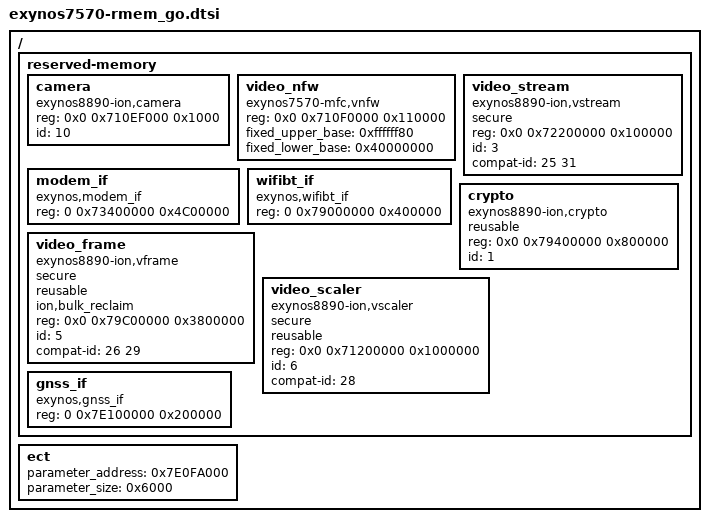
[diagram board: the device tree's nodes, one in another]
/*
 * SAMSUNG EXYNOS device tree source for reserved-memory
 *
 * Copyright (c) 2015 Samsung Electronics Co., Ltd.
 *		http://www.samsung.com
 *
 * This program is free software; you can redistribute it and/or modify
 * it under the terms of the GNU General Public License version 2 as
 * published by the Free Software Foundation.
*/

/memreserve/ 0x7E700000 0x100000;

/ {
	reserved-memory {
		#address-cells = <2>;
		#size-cells = <1>;
		ranges;

		camera {
			compatible = "exynos8890-ion,camera";
			reg = <0x0 0x710EF000 0x1000>;
			id = <10>;
		};

		video_nfw {
			compatible = "exynos7570-mfc,vnfw";
			reg = <0x0 0x710F0000 0x110000>;
			fixed_upper_base = <0xffffff80>;
			fixed_lower_base = <0x40000000>;
		};

		video_stream {
			compatible = "exynos8890-ion,vstream";
			secure;
			reg = <0x0 0x72200000 0x100000>;
			id = <3>;
			compat-id = <25 31>;
		};

		modem_if {
			compatible = "exynos,modem_if";
			reg = <0 0x73400000 0x4C00000>;
		};

		wifibt_if {
			compatible = "exynos,wifibt_if";
			reg = <0 0x79000000 0x400000>;
		};

		crypto {
			compatible = "exynos8890-ion,crypto";
			reusable;
			reg = <0x0 0x79400000 0x800000>;
			id = <1>;
		};

		video_frame {
			compatible = "exynos8890-ion,vframe";
			secure;
			reusable;
			ion,bulk_reclaim;
			reg = <0x0 0x79C00000 0x3800000>;
			id = <5>;
			compat-id = <26 29>;
		};

		video_scaler {
			compatible = "exynos8890-ion,vscaler";
			secure;
			reusable;
			reg = <0x0 0x71200000 0x1000000>;
			id = <6>;
			compat-id = <28>;
		};

		gnss_if {
			compatible = "exynos,gnss_if";
			reg = <0 0x7E100000 0x200000>;
		};

	};

	ect {
		parameter_address = <0x7E0FA000>;
		parameter_size = <0x6000>;
	};
};
